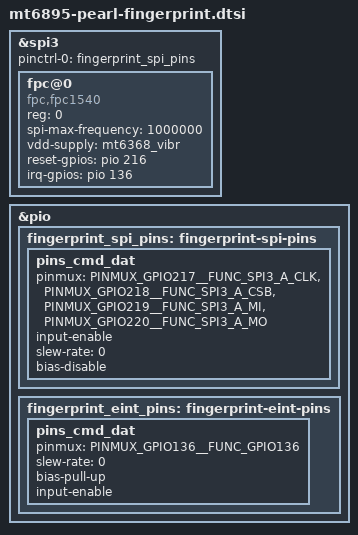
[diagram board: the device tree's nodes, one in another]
// SPDX-License-Identifier: (GPL-2.0 OR BSD-2-Clause)
/*
 * pearl 指纹传感器（FPC）。
 *
 * 硬件事实（两处独立来源一致）：
 *   - 设备 stock DTBO 的 fragment@28/29（compatible goodix,goodix-fp + fpc,gpio_irq）
 *   - vendor 仓 arch/arm64/boot/dts/vendor/mediatek/cust_mt6895_fingerprint.dtsi
 * 引脚：SPI3_A（CLK=217 CSB=218 MI=219 MO=220），复位 GPIO216，中断 GPIO136
 *       （EDGE_RISING + 内部上拉），供电 vfp(mt6368) / vibr(mt6368) / vufs18(mt6363)。
 * 方案判定：pearl stock ROM 的 HAL 是 /vendor/lib/hw/fingerprint.fpc.so
 *       ⇒ 这台机器是 FPC（DTBO 里的 goodix 节点是双物料残留）。
 *
 * 驱动：drivers/misc/fpc1540.c（从 xaga 分支 commit 2ae90e7bb1 移植），
 *       compatible "fpc,fpc1540"，暴露 /dev/fpc1540 给用户态 TA 栈
 *       （fpc1540-ta 的 ta_host，不需要厂商 TEE）。
 *       FPC 用 mt6368_vibr（1.8V）供电；同一组 SPI3_A 焊盘上若装的是
 *       Goodix 物料则用 mt6368_vfp（3.3V）—— 本机按 FPC 接。
 *
 * 上电后第一步验证：读 HWID（期望 0x1811）。
 */

&spi3 {
	status = "okay";
	pinctrl-names = "default";
	pinctrl-0 = <&fingerprint_spi_pins>;
	#address-cells = <1>;
	#size-cells = <0>;

	fpc@0 {
		compatible = "fpc,fpc1540";
		reg = <0>;
		spi-max-frequency = <1000000>;

		vdd-supply = <&mt6368_vibr>;
		reset-gpios = <&pio 216 GPIO_ACTIVE_HIGH>;
		irq-gpios = <&pio 136 GPIO_ACTIVE_HIGH>;

		status = "okay";
	};
};

&pio {
	fingerprint_spi_pins: fingerprint-spi-pins {
		pins_cmd_dat {
			pinmux = <PINMUX_GPIO217__FUNC_SPI3_A_CLK>,
				 <PINMUX_GPIO218__FUNC_SPI3_A_CSB>,
				 <PINMUX_GPIO219__FUNC_SPI3_A_MI>,
				 <PINMUX_GPIO220__FUNC_SPI3_A_MO>;
			/*
			 * SPI2 那边 setup.c 是显式设 IES/SMT 的；SPI3 这里靠
			 * pinctrl 属性让 MTK pinctrl 驱动去开输入缓冲
			 * （只设 pinmux 时 MISO 读回来恒为 0x00）。
			 */
			input-enable;
			slew-rate = <0>;
			bias-disable;
		};
	};

	fingerprint_eint_pins: fingerprint-eint-pins {
		pins_cmd_dat {
			pinmux = <PINMUX_GPIO136__FUNC_GPIO136>;
			slew-rate = <0>;
			bias-pull-up;
			input-enable;
		};
	};
};
